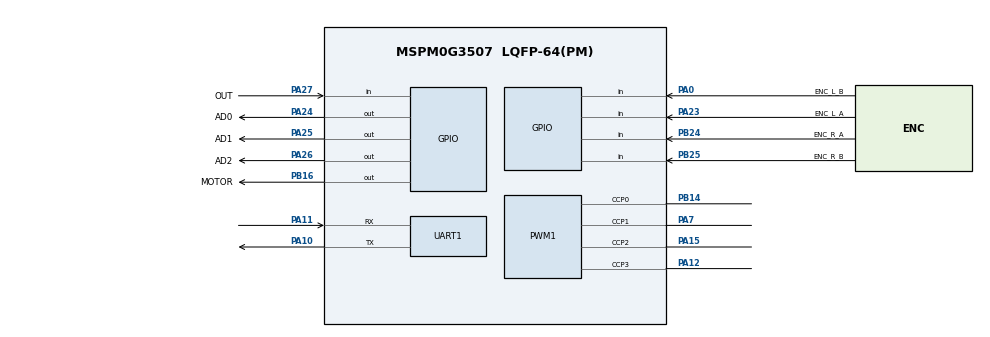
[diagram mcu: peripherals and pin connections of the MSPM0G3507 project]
/**
 * @cliArgs --device "MSPM0G350X" --part "Default" --package "LQFP-64(PM)" --product "mspm0_sdk@2.10.00.04"
 * @v2CliArgs --device "MSPM0G3507" --package "LQFP-64(PM)" --product "mspm0_sdk@2.10.00.04"
 * @versions {"tool":"1.26.2+4477"}
 */

const GPIO   = scripting.addModule("/ti/driverlib/GPIO", {}, false);
const GPIO1  = GPIO.addInstance();
const GPIO2  = GPIO.addInstance();
const GPIO3  = GPIO.addInstance();
const GPIO4  = GPIO.addInstance();
const GPIO5  = GPIO.addInstance();
const PWM    = scripting.addModule("/ti/driverlib/PWM", {}, false);
const PWM1   = PWM.addInstance();
const UART   = scripting.addModule("/ti/driverlib/UART", {}, false);
const UART1  = UART.addInstance();
const SYSCTL = scripting.addModule("/ti/driverlib/SYSCTL");

const Board  = scripting.addModule("/ti/driverlib/Board", {}, false);

/* ── 灰度AD0/AD1/AD2 ── */
GPIO1.$name                             = "GRP_GRAY";
GPIO1.associatedPins.create(3);
GPIO1.associatedPins[0].$name           = "AD0";
GPIO1.associatedPins[0].direction       = "OUTPUT";
GPIO1.associatedPins[0].initialValue    = "CLEARED";
GPIO1.associatedPins[0].pin.$assign     = "PA24";
GPIO1.associatedPins[1].$name           = "AD1";
GPIO1.associatedPins[1].direction       = "OUTPUT";
GPIO1.associatedPins[1].initialValue    = "CLEARED";
GPIO1.associatedPins[1].pin.$assign     = "PA25";
GPIO1.associatedPins[2].$name           = "AD2";
GPIO1.associatedPins[2].direction       = "OUTPUT";
GPIO1.associatedPins[2].initialValue    = "CLEARED";
GPIO1.associatedPins[2].pin.$assign     = "PA26";

/* ── 灰度OUT ── */
GPIO2.$name                             = "GRP_GRAY_OUT";
GPIO2.associatedPins.create(1);
GPIO2.associatedPins[0].$name           = "OUT";
GPIO2.associatedPins[0].direction       = "INPUT";
GPIO2.associatedPins[0].pin.$assign     = "PA27";

/* ── 继电器 GPIO_MOTOR_EN ── */
GPIO3.$name                             = "GRP_RELAY";
GPIO3.associatedPins.create(1);
GPIO3.associatedPins[0].$name           = "MOTOR";
GPIO3.associatedPins[0].direction       = "OUTPUT";
GPIO3.associatedPins[0].initialValue    = "CLEARED";
GPIO3.associatedPins[0].pin.$assign     = "PB16";

/* ── 左编码器 PA23/PA0 ── */
GPIO4.$name                             = "GRP_ENC_LEFT";
GPIO4.associatedPins.create(2);
GPIO4.associatedPins[0].$name           = "ENC_L_A";
GPIO4.associatedPins[0].direction       = "INPUT";
GPIO4.associatedPins[0].interruptEn     = true;
GPIO4.associatedPins[0].polarity        = "RISE_FALL";
GPIO4.associatedPins[0].pin.$assign     = "PA23";
GPIO4.associatedPins[1].$name           = "ENC_L_B";
GPIO4.associatedPins[1].direction       = "INPUT";
GPIO4.associatedPins[1].interruptEn     = true;
GPIO4.associatedPins[1].polarity        = "RISE_FALL";
GPIO4.associatedPins[1].pin.$assign     = "PA0";

/* ── 右编码器 PB24/PB25 ── */
GPIO5.$name                             = "GRP_ENC_RIGHT";
GPIO5.associatedPins.create(2);
GPIO5.associatedPins[0].$name           = "ENC_R_A";
GPIO5.associatedPins[0].direction       = "INPUT";
GPIO5.associatedPins[0].interruptEn     = true;
GPIO5.associatedPins[0].polarity        = "RISE_FALL";
GPIO5.associatedPins[0].pin.$assign     = "PB24";
GPIO5.associatedPins[1].$name           = "ENC_R_B";
GPIO5.associatedPins[1].direction       = "INPUT";
GPIO5.associatedPins[1].interruptEn     = true;
GPIO5.associatedPins[1].polarity        = "RISE_FALL";
GPIO5.associatedPins[1].pin.$assign     = "PB25";

/* ── 电机PWM: TIMA0, 4CC, 10kHz ── */
PWM1.$name                              = "PWM_DRIVE";
PWM1.timerCount                         = 3200;
PWM1.ccIndex                            = [0,1,2,3];
PWM1.peripheral.$assign                 = "TIMA0";
PWM1.peripheral.ccp0Pin.$assign         = "PB14";
PWM1.peripheral.ccp1Pin.$assign         = "PA7";
PWM1.peripheral.ccp2Pin.$assign         = "PA15";
PWM1.peripheral.ccp3Pin.$assign         = "PA12";
PWM1.PWM_CHANNEL_0.$name                = "ti_driverlib_pwm_PWMTimerCC0";
PWM1.PWM_CHANNEL_1.$name                = "ti_driverlib_pwm_PWMTimerCC1";
PWM1.PWM_CHANNEL_2.$name                = "ti_driverlib_pwm_PWMTimerCC2";
PWM1.PWM_CHANNEL_3.$name                = "ti_driverlib_pwm_PWMTimerCC3";
PWM1.ccp0PinConfig.$name                = "ti_driverlib_gpio_GPIOPinGeneric1";
PWM1.ccp0PinConfig.direction            = scripting.forceWrite("OUTPUT");
PWM1.ccp0PinConfig.hideOutputInversion  = scripting.forceWrite(false);
PWM1.ccp0PinConfig.onlyInternalResistor = scripting.forceWrite(false);
PWM1.ccp0PinConfig.passedPeripheralType = scripting.forceWrite("Digital");
PWM1.ccp1PinConfig.$name                = "ti_driverlib_gpio_GPIOPinGeneric2";
PWM1.ccp1PinConfig.direction            = scripting.forceWrite("OUTPUT");
PWM1.ccp1PinConfig.hideOutputInversion  = scripting.forceWrite(false);
PWM1.ccp1PinConfig.onlyInternalResistor = scripting.forceWrite(false);
PWM1.ccp1PinConfig.passedPeripheralType = scripting.forceWrite("Digital");
PWM1.ccp2PinConfig.$name                = "ti_driverlib_gpio_GPIOPinGeneric3";
PWM1.ccp2PinConfig.direction            = scripting.forceWrite("OUTPUT");
PWM1.ccp2PinConfig.hideOutputInversion  = scripting.forceWrite(false);
PWM1.ccp2PinConfig.onlyInternalResistor = scripting.forceWrite(false);
PWM1.ccp2PinConfig.passedPeripheralType = scripting.forceWrite("Digital");
PWM1.ccp3PinConfig.$name                = "ti_driverlib_gpio_GPIOPinGeneric4";
PWM1.ccp3PinConfig.direction            = scripting.forceWrite("OUTPUT");
PWM1.ccp3PinConfig.hideOutputInversion  = scripting.forceWrite(false);
PWM1.ccp3PinConfig.onlyInternalResistor = scripting.forceWrite(false);
PWM1.ccp3PinConfig.passedPeripheralType = scripting.forceWrite("Digital");

/* ── 串口 ── */
UART1.$name                              = "UART_JDY31";
UART1.targetBaudRate                     = 115200;
UART1.peripheral.$assign                 = "UART0";
UART1.peripheral.txPin.$assign           = "PA10";
UART1.peripheral.rxPin.$assign           = "PA11";
UART1.txPinConfig.$name                  = "ti_driverlib_gpio_GPIOPinGeneric5";
UART1.txPinConfig.direction              = scripting.forceWrite("OUTPUT");
UART1.txPinConfig.hideOutputInversion    = scripting.forceWrite(false);
UART1.txPinConfig.onlyInternalResistor   = scripting.forceWrite(false);
UART1.txPinConfig.passedPeripheralType   = scripting.forceWrite("Digital");
UART1.rxPinConfig.$name                  = "ti_driverlib_gpio_GPIOPinGeneric6";
UART1.rxPinConfig.hideOutputInversion    = scripting.forceWrite(false);
UART1.rxPinConfig.onlyInternalResistor   = scripting.forceWrite(false);
UART1.rxPinConfig.passedPeripheralType   = scripting.forceWrite("Digital");

SYSCTL.forceDefaultClkConfig = true;
